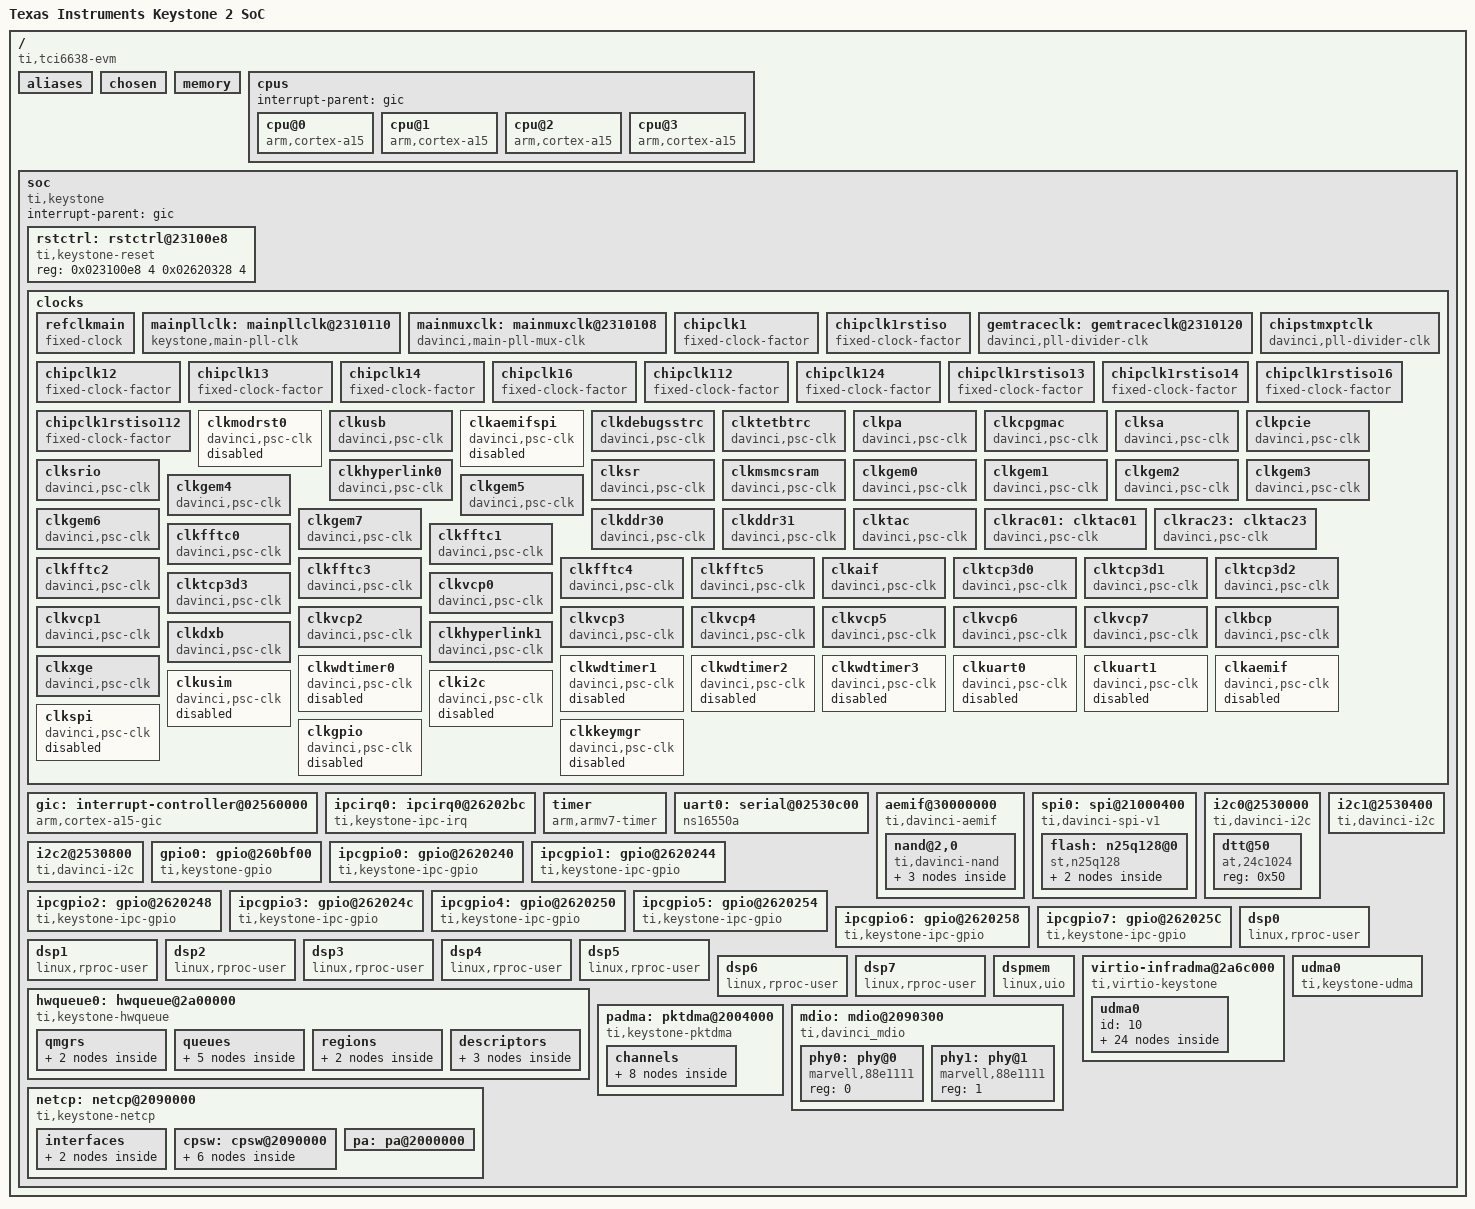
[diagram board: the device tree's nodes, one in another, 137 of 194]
/dts-v1/;
/include/ "skeleton.dtsi"

/ {
	model = "Texas Instruments Keystone 2 SoC";
	compatible = "ti,tci6638-evm";
	#address-cells = <2>;
	#size-cells = <2>;
	interrupt-parent = <&gic>;

	aliases {
		serial0	= &uart0;
		gpio0	= &gpio0;
	};

	chosen {
	};

	memory {
		reg = <0x00000000 0x80000000 0x00000000 0x20000000>;
	};

	cpus {
		interrupt-parent = <&gic>;

		cpu@0 {
			compatible = "arm,cortex-a15";
		};

		cpu@1 {
			compatible = "arm,cortex-a15";
		};

		cpu@2 {
			compatible = "arm,cortex-a15";
		};

		cpu@3 {
			compatible = "arm,cortex-a15";
		};
	};

	soc {
		#address-cells = <1>;
		#size-cells = <1>;
		compatible = "ti,keystone","simple-bus";
		interrupt-parent = <&gic>;
		ranges = <0x0 0x0 0x0 0xc0000000>;

		rstctrl:rstctrl@23100e8 {
			compatible = "ti,keystone-reset";
			reg = <0x023100e8 4	/* pll reset control reg */
				0x02620328 4>;	/* rstmux8 register */
		};

		clocks {
			#address-cells = <1>;
			#size-cells = <1>;
			ranges;

			refclkmain: refclkmain {
				#clock-cells = <0>;
				compatible = "fixed-clock";
				clock-frequency = <122880000>;
				clock-output-names = "refclk-main";
			};

			mainpllclk: mainpllclk@2310110 {
				#clock-cells = <0>;
				compatible = "keystone,main-pll-clk";
				clocks = <&refclkmain>;
				reg = <0x02310110 4	/* PLLCTRL PLLM */
					0x02620350 4>;	/* MAINPLL_CTL0 */
				pllm_lower_mask	= <0x3f>;
				pllm_upper_mask = <0x7f000>;
				pllm_upper_shift = <6>;
				plld_mask = <0x3f>;
				fixed_postdiv = <2>;
			};

			mainmuxclk: mainmuxclk@2310108 {
				#clock-cells = <0>;
				compatible = "davinci,main-pll-mux-clk";
				clocks = <&mainpllclk>, <&refclkmain>;
				reg = <0x02310108 4>;
				shift = <23>;
				width = <1>;
			};

			chipclk1: chipclk1 {
				#clock-cells = <0>;
				compatible = "fixed-clock-factor";
				clocks = <&mainmuxclk>;
				mult = <1>;
				div = <1>;
			};

			chipclk1rstiso: chipclk1rstiso {
				#clock-cells = <0>;
				compatible = "fixed-clock-factor";
				clocks = <&mainmuxclk>;
				mult = <1>;
				div = <1>;
			};

			gemtraceclk: gemtraceclk@2310120 {
				#clock-cells = <0>;
				compatible = "davinci,pll-divider-clk";
				clocks = <&mainmuxclk>;
				reg = <0x02310120 4>;
				shift = <0>;
				width = <8>;
			};

			chipstmxptclk: chipstmxptclk {
				#clock-cells = <0>;
				compatible = "davinci,pll-divider-clk";
				clocks = <&mainmuxclk>;
				reg = <0x02310164 4>;
				shift = <0>;
				width = <8>;
			};

			chipclk12: chipclk12 {
				#clock-cells = <0>;
				compatible = "fixed-clock-factor";
				clocks = <&chipclk1>;
				mult = <1>;
				div = <2>;
			};

			chipclk13: chipclk13 {
				#clock-cells = <0>;
				compatible = "fixed-clock-factor";
				clocks = <&chipclk1>;
				mult = <1>;
				div = <3>;
			};

			chipclk14: chipclk14 {
				#clock-cells = <0>;
				compatible = "fixed-clock-factor";
				clocks = <&chipclk1>;
				mult = <1>;
				div = <4>;
			};

			chipclk16: chipclk16 {
				#clock-cells = <0>;
				compatible = "fixed-clock-factor";
				clocks = <&chipclk1>;
				mult = <1>;
				div = <6>;
			};

			chipclk112: chipclk112 {
				#clock-cells = <0>;
				compatible = "fixed-clock-factor";
				clocks = <&chipclk1>;
				mult = <1>;
				div = <12>;
			};

			chipclk124: chipclk124 {
				#clock-cells = <0>;
				compatible = "fixed-clock-factor";
				clocks = <&chipclk1>;
				mult = <1>;
				div = <24>;
			};

			chipclk1rstiso13: chipclk1rstiso13 {
				#clock-cells = <0>;
				compatible = "fixed-clock-factor";
				clocks = <&chipclk1rstiso>;
				mult = <1>;
				div = <3>;
			};

			chipclk1rstiso14: chipclk1rstiso14 {
				#clock-cells = <0>;
				compatible = "fixed-clock-factor";
				clocks = <&chipclk1rstiso>;
				mult = <1>;
				div = <4>;
			};

			chipclk1rstiso16: chipclk1rstiso16 {
				#clock-cells = <0>;
				compatible = "fixed-clock-factor";
				clocks = <&chipclk1rstiso>;
				mult = <1>;
				div = <6>;
			};

			chipclk1rstiso112: chipclk1rstiso112 {
				#clock-cells = <0>;
				compatible = "fixed-clock-factor";
				clocks = <&chipclk1rstiso>;
				mult = <1>;
				div = <12>;
			};

			clkmodrst0: clkmodrst0 {
				#clock-cells = <0>;
				compatible = "davinci,psc-clk";
				clocks = <&chipclk16>;
				clock-output-names = "modrst0";
				status = "enabled";
				reg = <0x02350000 4096>;
			};


			clkusb: clkusb {
				#clock-cells = <0>;
				compatible = "davinci,psc-clk";
				clocks = <&chipclk16>;
				clock-output-names = "usb";
				reg = <0x02350000 4096>;
				lpsc = <2>;
			};

			clkaemifspi: clkaemifspi {
				#clock-cells = <0>;
				compatible = "davinci,psc-clk";
				clocks = <&chipclk16>;
				clock-output-names = "aemif-spi";
				reg = <0x02350000 4096>;
				status = "enabled";
				lpsc = <3>;
			};


			clkdebugsstrc: clkdebugsstrc {
				#clock-cells = <0>;
				compatible = "davinci,psc-clk";
				clocks = <&chipclk13>;
				clock-output-names = "debugss-trc";
				base-flags = "ignore-unused";
				reg = <0x02350000 4096>;
				lpsc = <5>;
				pd = <1>;
			};

			clktetbtrc: clktetbtrc {
				#clock-cells = <0>;
				compatible = "davinci,psc-clk";
				clocks = <&chipclk13>;
				clock-output-names = "tetb-trc";
				base-flags = "ignore-unused";
				reg = <0x02350000 4096>;
				lpsc = <6>;
				pd = <1>;
			};

			clkpa: clkpa {
				#clock-cells = <0>;
				compatible = "davinci,psc-clk";
				clocks = <&chipclk16>;
				clock-output-names = "pa";
				base-flags = "ignore-unused";
				reg = <0x02350000 4096>;
				lpsc = <7>;
				pd = <2>;
			};

			clkcpgmac: clkcpgmac {
				#clock-cells = <0>;
				compatible = "davinci,psc-clk";
				clocks = <&clkpa>;
				clock-output-names = "cpgmac";
				base-flags = "ignore-unused";
				reg = <0x02350000 4096>;
				lpsc = <8>;
				pd = <2>;
			};

			clksa: clksa {
				#clock-cells = <0>;
				compatible = "davinci,psc-clk";
				clocks = <&clkpa>;
				clock-output-names = "sa";
				base-flags = "ignore-unused";
				reg = <0x02350000 4096>;
				lpsc = <9>;
				pd = <2>;
			};

			clkpcie: clkpcie {
				#clock-cells = <0>;
				compatible = "davinci,psc-clk";
				clocks = <&chipclk12>;
				clock-output-names = "pcie";
				base-flags = "ignore-unused";
				reg = <0x02350000 4096>;
				lpsc = <10>;
				pd = <3>;
			};

			clksrio: clksrio {
				#clock-cells = <0>;
				compatible = "davinci,psc-clk";
				clocks = <&chipclk1rstiso13>;
				clock-output-names = "srio";
				base-flags = "ignore-unused";
				reg = <0x02350000 4096>;
				lpsc = <11>;
				pd = <4>;
			};

			clkhyperlink0: clkhyperlink0 {
				#clock-cells = <0>;
				compatible = "davinci,psc-clk";
				clocks = <&chipclk12>;
				clock-output-names = "hyperlink-0";
				base-flags = "ignore-unused";
				reg = <0x02350000 4096>;
				lpsc = <12>;
				pd = <5>;
			};

			clksr: clksr {
				#clock-cells = <0>;
				compatible = "davinci,psc-clk";
				clocks = <&chipclk1rstiso112>;
				clock-output-names = "sr";
				base-flags = "ignore-unused";
				reg = <0x02350000 4096>;
				lpsc = <13>;
				pd = <6>;
			};

			clkmsmcsram: clkmsmcsram {
				#clock-cells = <0>;
				compatible = "davinci,psc-clk";
				clocks = <&chipclk1>;
				clock-output-names = "msmcsram";
				base-flags = "ignore-unused";
				reg = <0x02350000 4096>;
				lpsc = <14>;
				pd = <7>;
			};

			clkgem0: clkgem0 {
				#clock-cells = <0>;
				compatible = "davinci,psc-clk";
				clocks = <&chipclk1>;
				clock-output-names = "gem0";
				base-flags = "ignore-unused";
				reg = <0x02350000 4096>;
				lpsc = <15>;
				pd = <8>;
			};

			clkgem1: clkgem1 {
				#clock-cells = <0>;
				compatible = "davinci,psc-clk";
				clocks = <&chipclk1>;
				clock-output-names = "gem1";
				base-flags = "ignore-unused";
				reg = <0x02350000 4096>;
				lpsc = <16>;
				pd = <9>;
			};

			clkgem2: clkgem2 {
				#clock-cells = <0>;
				compatible = "davinci,psc-clk";
				clocks = <&chipclk1>;
				clock-output-names = "gem2";
				base-flags = "ignore-unused";
				reg = <0x02350000 4096>;
				lpsc = <17>;
				pd = <10>;
			};

			clkgem3: clkgem3 {
				#clock-cells = <0>;
				compatible = "davinci,psc-clk";
				clocks = <&chipclk1>;
				clock-output-names = "gem3";
				base-flags = "ignore-unused";
				reg = <0x02350000 4096>;
				lpsc = <18>;
				pd = <11>;
			};

			clkgem4: clkgem4 {
				#clock-cells = <0>;
				compatible = "davinci,psc-clk";
				clocks = <&chipclk1>;
				clock-output-names = "gem4";
				base-flags = "ignore-unused";
				reg = <0x02350000 4096>;
				lpsc = <19>;
				pd = <12>;
			};

			clkgem5: clkgem5 {
				#clock-cells = <0>;
				compatible = "davinci,psc-clk";
				clocks = <&chipclk1>;
				clock-output-names = "gem5";
				base-flags = "ignore-unused";
				reg = <0x02350000 4096>;
				lpsc = <20>;
				pd = <13>;
			};

			clkgem6: clkgem6 {
				#clock-cells = <0>;
				compatible = "davinci,psc-clk";
				clocks = <&chipclk1>;
				clock-output-names = "gem6";
				base-flags = "ignore-unused";
				reg = <0x02350000 4096>;
				lpsc = <21>;
				pd = <14>;
			};

			clkgem7: clkgem7 {
				#clock-cells = <0>;
				compatible = "davinci,psc-clk";
				clocks = <&chipclk1>;
				clock-output-names = "gem7";
				base-flags = "ignore-unused";
				reg = <0x02350000 4096>;
				lpsc = <22>;
				pd = <15>;
			};

			clkddr30: clkddr30 {
				#clock-cells = <0>;
				compatible = "davinci,psc-clk";
				clocks = <&chipclk12>;
				clock-output-names = "ddr3-0";
				base-flags = "ignore-unused";
				reg = <0x02350000 4096>;
				lpsc = <23>;
				pd = <16>;
			};

			clkddr31: clkddr31 {
				#clock-cells = <0>;
				compatible = "davinci,psc-clk";
				clocks = <&chipclk13>;
				clock-output-names = "ddr3-1";
				base-flags = "ignore-unused";
				reg = <0x02350000 4096>;
				lpsc = <24>;
				pd = <16>;
			};

			clktac: clktac {
				#clock-cells = <0>;
				compatible = "davinci,psc-clk";
				clocks = <&chipclk13>;
				clock-output-names = "tac";
				base-flags = "ignore-unused";
				reg = <0x02350000 4096>;
				lpsc = <25>;
				pd = <17>;
			};

			clkrac01: clktac01 {
				#clock-cells = <0>;
				compatible = "davinci,psc-clk";
				clocks = <&chipclk13>;
				clock-output-names = "rac-01";
				base-flags = "ignore-unused";
				reg = <0x02350000 4096>;
				lpsc = <26>;
				pd = <17>;
			};

			clkrac23: clktac23 {
				#clock-cells = <0>;
				compatible = "davinci,psc-clk";
				clocks = <&chipclk13>;
				clock-output-names = "rac-23";
				base-flags = "ignore-unused";
				reg = <0x02350000 4096>;
				lpsc = <27>;
				pd = <18>;
			};

			clkfftc0: clkfftc0 {
				#clock-cells = <0>;
				compatible = "davinci,psc-clk";
				clocks = <&chipclk13>;
				clock-output-names = "fftc-0";
				base-flags = "ignore-unused";
				reg = <0x02350000 4096>;
				lpsc = <28>;
				pd = <19>;
			};

			clkfftc1: clkfftc1 {
				#clock-cells = <0>;
				compatible = "davinci,psc-clk";
				clocks = <&chipclk13>;
				clock-output-names = "fftc-1";
				base-flags = "ignore-unused";
				reg = <0x02350000 4096>;
				lpsc = <29>;
				pd = <19>;
			};

			clkfftc2: clkfftc2 {
				#clock-cells = <0>;
				compatible = "davinci,psc-clk";
				clocks = <&chipclk13>;
				clock-output-names = "fftc-2";
				base-flags = "ignore-unused";
				reg = <0x02350000 4096>;
				lpsc = <30>;
				pd = <20>;
			};

			clkfftc3: clkfftc3 {
				#clock-cells = <0>;
				compatible = "davinci,psc-clk";
				clocks = <&chipclk13>;
				clock-output-names = "fftc-3";
				base-flags = "ignore-unused";
				reg = <0x02350000 4096>;
				lpsc = <31>;
				pd = <20>;
			};

			clkfftc4: clkfftc4 {
				#clock-cells = <0>;
				compatible = "davinci,psc-clk";
				clocks = <&chipclk13>;
				clock-output-names = "fftc-4";
				base-flags = "ignore-unused";
				reg = <0x02350000 4096>;
				lpsc = <32>;
				pd = <20>;
			};

			clkfftc5: clkfftc5 {
				#clock-cells = <0>;
				compatible = "davinci,psc-clk";
				clocks = <&chipclk13>;
				clock-output-names = "fftc-5";
				base-flags = "ignore-unused";
				reg = <0x02350000 4096>;
				lpsc = <33>;
				pd = <20>;
			};

			clkaif: clkaif {
				#clock-cells = <0>;
				compatible = "davinci,psc-clk";
				clocks = <&chipclk13>;
				clock-output-names = "aif";
				base-flags = "ignore-unused";
				reg = <0x02350000 4096>;
				lpsc = <34>;
				pd = <21>;
			};

			clktcp3d0: clktcp3d0 {
				#clock-cells = <0>;
				compatible = "davinci,psc-clk";
				clocks = <&chipclk13>;
				clock-output-names = "tcp3d-0";
				base-flags = "ignore-unused";
				reg = <0x02350000 4096>;
				lpsc = <35>;
				pd = <22>;
			};

			clktcp3d1: clktcp3d1 {
				#clock-cells = <0>;
				compatible = "davinci,psc-clk";
				clocks = <&chipclk13>;
				clock-output-names = "tcp3d-1";
				base-flags = "ignore-unused";
				reg = <0x02350000 4096>;
				lpsc = <36>;
				pd = <22>;
			};

			clktcp3d2: clktcp3d2 {
				#clock-cells = <0>;
				compatible = "davinci,psc-clk";
				clocks = <&chipclk13>;
				clock-output-names = "tcp3d-2";
				base-flags = "ignore-unused";
				reg = <0x02350000 4096>;
				lpsc = <37>;
				pd = <23>;
			};

			clktcp3d3: clktcp3d3 {
				#clock-cells = <0>;
				compatible = "davinci,psc-clk";
				clocks = <&chipclk13>;
				clock-output-names = "tcp3d-3";
				base-flags = "ignore-unused";
				reg = <0x02350000 4096>;
				lpsc = <38>;
				pd = <23>;
			};

			clkvcp0: clkvcp0 {
				#clock-cells = <0>;
				compatible = "davinci,psc-clk";
				clocks = <&chipclk13>;
				clock-output-names = "vcp-0";
				base-flags = "ignore-unused";
				reg = <0x02350000 4096>;
				lpsc = <39>;
				pd = <24>;
			};

			clkvcp1: clkvcp1 {
				#clock-cells = <0>;
				compatible = "davinci,psc-clk";
				clocks = <&chipclk13>;
				clock-output-names = "vcp-1";
				base-flags = "ignore-unused";
				reg = <0x02350000 4096>;
				lpsc = <40>;
				pd = <24>;
			};

			clkvcp2: clkvcp2 {
				#clock-cells = <0>;
				compatible = "davinci,psc-clk";
				clocks = <&chipclk13>;
				clock-output-names = "vcp-2";
				base-flags = "ignore-unused";
				reg = <0x02350000 4096>;
				lpsc = <41>;
				pd = <24>;
			};

			clkvcp3: clkvcp3 {
				#clock-cells = <0>;
				compatible = "davinci,psc-clk";
				clocks = <&chipclk13>;
				clock-output-names = "vcp-3";
				base-flags = "ignore-unused";
				reg = <0x02350000 4096>;
				lpsc = <42>;
				pd = <24>;
			};

			clkvcp4: clkvcp4 {
				#clock-cells = <0>;
				compatible = "davinci,psc-clk";
				clocks = <&chipclk13>;
				clock-output-names = "vcp-4";
				base-flags = "ignore-unused";
				reg = <0x02350000 4096>;
				lpsc = <43>;
				pd = <25>;
			};

			clkvcp5: clkvcp5 {
				#clock-cells = <0>;
				compatible = "davinci,psc-clk";
				clocks = <&chipclk13>;
				clock-output-names = "vcp-5";
				base-flags = "ignore-unused";
				reg = <0x02350000 4096>;
				lpsc = <44>;
				pd = <25>;
			};

			clkvcp6: clkvcp6 {
				#clock-cells = <0>;
				compatible = "davinci,psc-clk";
				clocks = <&chipclk13>;
				clock-output-names = "vcp-6";
				base-flags = "ignore-unused";
				reg = <0x02350000 4096>;
				lpsc = <45>;
				pd = <25>;
			};

			clkvcp7: clkvcp7 {
				#clock-cells = <0>;
				compatible = "davinci,psc-clk";
				clocks = <&chipclk13>;
				clock-output-names = "vcp-7";
				base-flags = "ignore-unused";
				reg = <0x02350000 4096>;
				lpsc = <46>;
				pd = <25>;
			};

			clkbcp: clkbcp {
				#clock-cells = <0>;
				compatible = "davinci,psc-clk";
				clocks = <&chipclk13>;
				clock-output-names = "bcp";
				base-flags = "ignore-unused";
				reg = <0x02350000 4096>;
				lpsc = <47>;
				pd = <26>;
			};

			clkdxb: clkdxb {
				#clock-cells = <0>;
				compatible = "davinci,psc-clk";
				clocks = <&chipclk13>;
				clock-output-names = "dxb";
				base-flags = "ignore-unused";
				reg = <0x02350000 4096>;
				lpsc = <48>;
				pd = <27>;
			};

			clkhyperlink1: clkhyperlink1 {
				#clock-cells = <0>;
				compatible = "davinci,psc-clk";
				clocks = <&chipclk12>;
				clock-output-names = "hyperlink-1";
				base-flags = "ignore-unused";
				reg = <0x02350000 4096>;
				lpsc = <49>;
				pd = <28>;
			};

			clkxge: clkxge {
				#clock-cells = <0>;
				compatible = "davinci,psc-clk";
				clocks = <&chipclk13>;
				clock-output-names = "xge";
				base-flags = "ignore-unused";
				reg = <0x02350000 4096>;
				lpsc = <50>;
				pd = <29>;
			};

			clkwdtimer0: clkwdtimer0 {
				#clock-cells = <0>;
				compatible = "davinci,psc-clk";
				clocks = <&clkmodrst0>;
				clock-output-names = "timer0";
				status = "enabled";
				reg = <0x02350000 4096>;
			};

			clkwdtimer1: clkwdtimer1 {
				#clock-cells = <0>;
				compatible = "davinci,psc-clk";
				clocks = <&clkmodrst0>;
				clock-output-names = "timer1";
				status = "enabled";
				reg = <0x02350000 4096>;
			};

			clkwdtimer2: clkwdtimer2 {
				#clock-cells = <0>;
				compatible = "davinci,psc-clk";
				clocks = <&clkmodrst0>;
				clock-output-names = "timer2";
				status = "enabled";
				reg = <0x02350000 4096>;
			};

			clkwdtimer3: clkwdtimer3 {
				#clock-cells = <0>;
				compatible = "davinci,psc-clk";
				clocks = <&clkmodrst0>;
				clock-output-names = "timer3";
				status = "enabled";
				reg = <0x02350000 4096>;
			};

			clkuart0: clkuart0 {
				#clock-cells = <0>;
				compatible = "davinci,psc-clk";
				clocks = <&clkmodrst0>;
				clock-output-names = "uart0";
				status = "enabled";
				reg = <0x02350000 4096>;
			};

			clkuart1: clkuart1 {
				#clock-cells = <0>;
				compatible = "davinci,psc-clk";
				clocks = <&clkmodrst0>;
				clock-output-names = "uart1";
				status = "enabled";
				reg = <0x02350000 4096>;
			};

			clkaemif: clkaemif {
				#clock-cells = <0>;
				compatible = "davinci,psc-clk";
				clocks = <&clkaemifspi>;
				clock-output-names = "aemif";
				status = "enabled";
				reg = <0x02350000 4096>;
			};

			clkusim: clkusim {
				#clock-cells = <0>;
				compatible = "davinci,psc-clk";
				clocks = <&clkmodrst0>;
				clock-output-names = "usim";
				status = "enabled";
				reg = <0x02350000 4096>;
			};

			clki2c: clki2c {
				#clock-cells = <0>;
				compatible = "davinci,psc-clk";
				clocks = <&clkmodrst0>;
				clock-output-names = "i2c";
				status = "enabled";
				reg = <0x02350000 4096>;
			};

			clkspi: clkspi {
				#clock-cells = <0>;
				compatible = "davinci,psc-clk";
				clocks = <&clkaemifspi>;
				clock-output-names = "spi";
				status = "enabled";
				reg = <0x02350000 4096>;
			};

			clkgpio: clkgpio {
				#clock-cells = <0>;
				compatible = "davinci,psc-clk";
				clocks = <&clkmodrst0>;
				clock-output-names = "gpio";
				status = "enabled";
				reg = <0x02350000 4096>;
			};

			clkkeymgr: clkkeymgr {
				#clock-cells = <0>;
				compatible = "davinci,psc-clk";
				clocks = <&clkmodrst0>;
				clock-output-names = "keymgr";
				status = "enabled";
				reg = <0x02350000 4096>;
			};

		};

		gic:	interrupt-controller@02560000 {
			compatible = "arm,cortex-a15-gic";
			#interrupt-cells = <3>;
			#size-cells = <0>;
			#address-cells = <1>;
			interrupt-controller;
			reg = <0x02561000 0x1000>,
			      <0x02562000 0x2000>;
		};

		ipcirq0: ipcirq0@26202bc {	/* ipc irq chip */
			compatible = "ti,keystone-ipc-irq";
			reg  = <0x026202a0 4	/* host ack register */
			        0x02620260 4>;	/* ipc host interrupt generation register */
			interrupts = <0 4 0x101>;/* it should match the value in irqs.h */
						 /* following is the source id to irq mapping
						   SRCS0 <-> ipc hw irq 0 ... SRCS27 <-> ipc hw irq 27
						   note that SRCS0 is bit 4 in ipc register */
			interrupt-controller;
			#interrupt-cells = <2>;
		};

		timer {
			compatible = "arm,armv7-timer";
			interrupts = <1 13 0xf08 1 14 0xf08>;
			clock-frequency = <133666666>; /* Freq in Hz - optional */
		};

		uart0:	serial@02530c00 {
			compatible	= "ns16550a";
			current-speed	= <115200>;
			reg-shift	= <2>;
			reg-io-width	= <4>;
			reg		= <0x02530c00 0x100>;
			clocks		= <&clkuart0>;
			interrupts	= <0 277 0xf01>;
		};

		aemif@30000000 {
			compatible = "ti,davinci-aemif";
			#address-cells = <2>;
			#size-cells = <1>;
			reg = <0x21000A00 0x100>;
			ranges = <2 0 0x30000000 0x08000000
				3 0 0x34000000 0x04000000
				4 0 0x38000000 0x04000000
				5 0 0x3C000000 0x04000000
				6 0 0x21000A00 0x100>;
			clocks = <&clkaemif>;
			clock-names = "aemif";

			nand@2,0 {
				compatible = "ti,davinci-nand";
				reg = <2 0x0 0x8000000
					6 0x0 0x100>;
				#address-cells = <1>;
				#size-cells = <1>;
				ti,davinci-chipselect = <0>;
				ti,davinci-mask-ale = <0x2000>;
				ti,davinci-mask-cle = <0x4000>;
				ti,davinci-mask-chipsel = <0>;
				ti,davinci-ecc-mode = "hw";
				ti,davinci-ecc-bits = <4>;
				ti,davinci-nand-use-bbt;
				ti,davinci-no-subpage-write;
				clocks = <&clkaemif>;
				clock-names = "aemif";

				partition@0 {
					label = "u-boot";
					reg = <0x0 0x100000>;
					read-only;
				};

				partition@100000 {
					label = "params";
					reg = <0x100000 0x80000>;
					read-only;
				};

				partition@180000 {
					label = "ubifs";
					reg = <0x180000 0x7e80000>;
				};
			};
		};

		spi0:spi@21000400 {
			#address-cells			= <1>;
			#size-cells			= <0>;
			compatible			= "ti,davinci-spi-v1";
			reg				= <0x21000400 0x200>;
			ti,davinci-spi-num-cs		= <4>;
			ti,davinci-spi-intr-line	= <0>;
			interrupts			= <0 292 0xf01>;
			clocks				= <&clkspi>;

			flash: n25q128@0 {
				#address-cells = <1>;
				#size-cells = <1>;
				compatible = "st,n25q128","st,m25p";
				spi-max-frequency = <30000000>;
				reg = <0>;

				partition@0 {
					label = "u-boot-spl";
					reg = <0x0 0x80000>;
					read-only;
				};

				partition@1 {
					label = "test";
					reg = <0x80000 0xf80000>;
				};
			};
		};

		i2c0@2530000 {
			compatible = "ti,davinci-i2c";
			reg = <0x02530000 0x400>;
			clock-frequency = <100000>;
			clocks		= <&clki2c>;
			interrupts	= <0 283 0xf01>;
			#address-cells = <1>;
			#size-cells = <0>;

			dtt@50 {
				compatible = "at,24c1024";
				reg = <0x50>;
			};
		};

		i2c1@2530400 {
			compatible = "ti,davinci-i2c";
			reg = <0x02530400 0x400>;
			clock-frequency = <100000>;
			clocks		= <&clki2c>;
			interrupts	= <0 286 0xf01>;
			#address-cells = <1>;
			#size-cells = <0>;

		};

		i2c2@2530800 {
			compatible = "ti,davinci-i2c";
			reg = <0x02530800 0x400>;
			clock-frequency = <100000>;
			clocks		= <&clki2c>;
			interrupts	= <0 289 0xf01>;
			#address-cells = <1>;
			#size-cells = <0>;

		};

		gpio0: gpio@260bf00 {
			compatible = "ti,keystone-gpio";
			reg = <0x0260bf00 0x10
				0x0260bf10 0x28>;
			gpio-controller;
			#gpio-cells = <2>;
			/* HW Interrupts mapped to GPIO pins */
			interrupts = <0 120 0xf01 0 121 0xf01 0 122 0xf01 0 123 0xf01 0 124 0xf01
					0 125 0xf01 0 126 0xf01 0 127 0xf01 0 128 0xf01 0 129 0xf01
					0 130 0xf01 0 131 0xf01 0 132 0xf01 0 133 0xf01 0 134 0xf01
					0 135 0xf01 0 136 0xf01 0 137 0xf01 0 138 0xf01 0 139 0xf01
					0 140 0xf01 0 141 0xf01 0 142 0xf01 0 143 0xf01 0 144 0xf01
					0 145 0xf01 0 146 0xf01 0 147 0xf01 0 148 0xf01 0 149 0xf01
					0 150 0xf01 0 151 0xf01>;
			interrupt-controller;
			#interrupt-cells = <2>;
			clocks = <&clkgpio>;
			clock-names = "gpio";
		};

		ipcgpio0: gpio@2620240 {
			compatible = "ti,keystone-ipc-gpio";
			reg = <0x02620240 4>;
			gpio-controller;
			#gpio-cells = <2>;
		};

		ipcgpio1: gpio@2620244 {
			compatible = "ti,keystone-ipc-gpio";
			reg = <0x02620244 4>;
			gpio-controller;
			#gpio-cells = <2>;
		};

		ipcgpio2: gpio@2620248 {
			compatible = "ti,keystone-ipc-gpio";
			reg = <0x02620248 4>;
			gpio-controller;
			#gpio-cells = <2>;
		};

		ipcgpio3: gpio@262024c {
			compatible = "ti,keystone-ipc-gpio";
			reg = <0x0262024c 4>;
			gpio-controller;
			#gpio-cells = <2>;
		};

		ipcgpio4: gpio@2620250 {
			compatible = "ti,keystone-ipc-gpio";
			reg = <0x02620250 4>;
			gpio-controller;
			#gpio-cells = <2>;
		};

		ipcgpio5: gpio@2620254 {
			compatible = "ti,keystone-ipc-gpio";
			reg = <0x02620254 4>;
			gpio-controller;
			#gpio-cells = <2>;
		};

		ipcgpio6: gpio@2620258 {
			compatible = "ti,keystone-ipc-gpio";
			reg = <0x02620258 4>;
			gpio-controller;
			#gpio-cells = <2>;
		};

		ipcgpio7: gpio@262025C {
			compatible = "ti,keystone-ipc-gpio";
			reg = <0x0262025C 4>;
			gpio-controller;
			#gpio-cells = <2>;
		};

		dsp0: dsp0 {
			compatible = "linux,rproc-user";
			reg = <0x02620040 4
			       0x0235083c 4
			       0x02350a3c 4
			       0x02620240 4
			       0x10800000 0x00100000>;
			reg-names = "boot-address", "psc-mdstat", "psc-mdctl", "ipcgr", "l2ram";
			interrupt-parent = <&ipcirq0>;
			interrupts = <8 0 0 0>;
			kick-gpio = <&ipcgpio0 27 0>;
			clocks = <&clkgem0>;
		};

		dsp1: dsp1 {
			compatible = "linux,rproc-user";
			reg = <0x02620044 4
			       0x02350840 4
			       0x02350a40 4
			       0x02620244 4
			       0x11800000 0x00100000>;
			reg-names = "boot-address", "psc-mdstat", "psc-mdctl", "ipcgr", "l2ram";
			interrupt-parent = <&ipcirq0>;
			interrupts = <9 0 1 0>;
			kick-gpio = <&ipcgpio1 27 0>;
			clocks = <&clkgem1>;
		};

		dsp2: dsp2 {
			compatible = "linux,rproc-user";
			reg = <0x02620048 4
			       0x02350844 4
			       0x02350a44 4
			       0x02620248 4
			       0x12800000 0x00100000>;
			reg-names = "boot-address", "psc-mdstat", "psc-mdctl", "ipcgr", "l2ram";
			interrupt-parent = <&ipcirq0>;
			interrupts = <10 0 2 0>;
			kick-gpio = <&ipcgpio2 27 0>;
			clocks = <&clkgem2>;
		};

		dsp3: dsp3 {
			compatible = "linux,rproc-user";
			reg = <0x0262004c 4
			       0x02350848 4
			       0x02350a48 4
			       0x0262024c 4
			       0x13800000 0x00100000>;
			reg-names = "boot-address", "psc-mdstat", "psc-mdctl", "ipcgr", "l2ram";
			interrupt-parent = <&ipcirq0>;
			interrupts = <11 0 3 0>;
			kick-gpio = <&ipcgpio3 27 0>;
			clocks = <&clkgem3>;
		};

		dsp4: dsp4 {
			compatible = "linux,rproc-user";
			reg = <0x02620050 4
			       0x0235084C 4
			       0x02350a4C 4
			       0x02620250 4
			       0x14800000 0x00100000>;
			reg-names = "boot-address", "psc-mdstat", "psc-mdctl", "ipcgr", "l2ram";
			interrupt-parent = <&ipcirq0>;
			interrupts = <12 0 4 0>;
			kick-gpio = <&ipcgpio4 27 0>;
			clocks = <&clkgem4>;
		};

		dsp5: dsp5 {
			compatible = "linux,rproc-user";
			reg = <0x02620054 4
			       0x02350850 4
			       0x02350a50 4
			       0x02620254 4
			       0x15800000 0x00100000>;
			reg-names = "boot-address", "psc-mdstat", "psc-mdctl", "ipcgr", "l2ram";
			interrupt-parent = <&ipcirq0>;
			interrupts = <13 0 5 0>;
			kick-gpio = <&ipcgpio5 27 0>;
			clocks = <&clkgem5>;
		};

		dsp6: dsp6 {
			compatible = "linux,rproc-user";
			reg = <0x02620058 4
			       0x02350854 4
			       0x02350a54 4
			       0x02620258 4
			       0x16800000 0x00100000>;
			reg-names = "boot-address", "psc-mdstat", "psc-mdctl", "ipcgr", "l2ram";
			interrupt-parent = <&ipcirq0>;
			interrupts = <14 0 6 0>;
			kick-gpio = <&ipcgpio6 27 0>;
			clocks = <&clkgem6>;
		};

		dsp7: dsp7 {
			compatible = "linux,rproc-user";
			reg = <0x0262005C 4
			       0x02350858 4
			       0x02350a58 4
			       0x0262025C 4
			       0x17800000 0x00100000>;
			reg-names = "boot-address", "psc-mdstat", "psc-mdctl", "ipcgr", "l2ram";
			interrupt-parent = <&ipcirq0>;
			interrupts = <15 0 7 0>;
			kick-gpio = <&ipcgpio7 27 0>;
			clocks = <&clkgem7>;
		};

		dspmem: dspmem {
			compatible = "linux,uio";
			reg  = <0x0c000000 0x00200000	/* msmc ram */
				0xa0000000 0x20000000>;	/* corepac's ddr3 */
			reg-names = "msmcram", "ddr3";
		};

		hwqueue0: hwqueue@2a00000 {
			compatible = "ti,keystone-hwqueue";
			#address-cells = <1>;
			#size-cells = <1>;
			ranges;
			range		= <0 0x4000>;
			linkram0	= <0x100000 0x8000>;
			linkram1	= <0x0 0x10000>;

			qmgrs {
				#address-cells = <1>;
				#size-cells = <1>;
				ranges;
				qmgr0 {
					managed-queues = <0 0x2000>;	/* managed queues */
					reg = <0x2a40000 0x20000	/* 0 - peek	*/
					       0x2a06000 0x400		/* 1 - status	*/
					       0x2a02000 0x1000		/* 2 - config	*/
					       0x2a03000 0x1000		/* 3 - region	*/
					       0x2a80000 0x20000	/* 4 - push	*/
					       0x2a80000 0x20000>;	/* 5 - pop	*/
				};

				qmgr1 {
					managed-queues = <0x2000 0x2000>;	/* managed queues */
					reg = <0x2a60000 0x20000	/* 0 - peek	*/
					       0x2a06400 0x400		/* 1 - status	*/
					       0x2a04000 0x1000		/* 2 - config	*/
					       0x2a05000 0x1000		/* 3 - region	*/
					       0x2aa0000 0x20000	/* 4 - push	*/
					       0x2aa0000 0x20000>;	/* 5 - pop	*/
				};
			};
			queues {
				qpend-arm-low {
					values = <652 20>;
					interrupts = <0 40 0xf04 0 41 0xf04 0 42 0xf04 0 43 0xf04
						      0 44 0xf04 0 45 0xf04 0 46 0xf04 0 47 0xf04>;
					reserved;
				};
				qpend-arm-hi {
					values = <8704 32>;
					interrupts = <0 48 0xf04 0 49 0xf04 0 50 0xf04 0 51 0xf04
						      0 52 0xf04 0 53 0xf04 0 54 0xf04 0 55 0xf04
						      0 56 0xf04 0 57 0xf04 0 58 0xf04 0 59 0xf04
						      0 60 0xf04 0 61 0xf04 0 62 0xf04 0 63 0xf04
						      0 64 0xf04 0 65 0xf04 0 66 0xf04 0 59 0xf04
						      0 68 0xf04 0 69 0xf04 0 70 0xf04 0 71 0xf04
						      0 72 0xf04 0 73 0xf04 0 74 0xf04 0 75 0xf04
						      0 76 0xf04 0 77 0xf04 0 78 0xf04 0 79 0xf04>;
					reserved;
				};
				general {
					values = <4000 64>;
				};
				pa {
					values = <640 9>;
					reserved;
				};
				infradma {
					values = <800 12>;
					reserved;
				};
			};
			regions {
				#address-cells = <1>;
				#size-cells = <1>;
				ranges;
				region-12 {
					id = <12>;
					values	= <2048 128>;	/* num_desc desc_size */
					link-index = <0x4000>;
				};
				region-13 {
					id = <13>;
					values	= <2048 256>;	/* num_desc desc_size */
					link-index = <0x4800>;
				};
			};
			descriptors {
				pool-net {
					values = <2048 128>;	/* num_desc desc_size */
					region-id = <12>;
				};
				pool-rio {
					values = <128 256>;
					region-id = <13>;
				};
				pool-udma {
					values = <1636 256>;	/* num_desc desc_size */
					region-id = <13>;
				};
			};
		}; /* hwqueue0 */

		virtio-infradma@2a6c000 {
			compatible = "ti,virtio-keystone";
			reg = <0x2a08000 0x100		/* 0 - global  */
			       0x2a08400 0x400		/* 1 - txchan  */
			       0x2a08800 0x400		/* 2 - rxchan  */
			       0x2a08c00 0x080		/* 3 - txsched */
			       0x2a09000 0x400>;	/* 4 - rxflow  */
			loop-back;
			/* big-endian; */
			enable-all;
			debug;
			/* rx-priority = <0>; */
			/* tx-priority = <0>; */
			queue-managers = <0x23a80000 0x23a90000
					  0x23aa0000 0x23ab0000>;

			udma0 {
				id = <10>;
				udmatx0 {
					transmit;
					label		= "udmatx0";
					pool		= "pool-udma";
					submit-queue	= <800>;
					/* complete-queue  = <0> */
					/* debug; */
					channel		= <0>;
					priority	= <1>;
					flowtag		= <0>;
				};
				udmatx1 {
					transmit;
					label		= "udmatx1";
					pool		= "pool-udma";
					submit-queue	= <801>;
					/* complete-queue  = <1> */
					/* debug; */
					channel		= <1>;
					priority	= <1>;
					flowtag		= <1>;
				};
				udmatx2 {
					transmit;
					label		= "udmatx2";
					pool		= "pool-udma";
					submit-queue	= <802>;
					/* complete-queue  = <2> */
					/* debug; */
					channel		= <2>;
					priority	= <1>;
					flowtag		= <2>;
				};
				udmatx3 {
					transmit;
					label		= "udmatx3";
					pool		= "pool-udma";
					submit-queue	= <803>;
					/* complete-queue  = <3> */
					/* debug; */
					channel		= <3>;
					priority	= <1>;
					flowtag		= <3>;
				};
				udmatx4 {
					transmit;
					label		= "udmatx4";
					pool		= "pool-udma";
					submit-queue	= <804>;
					/* complete-queue  = <4> */
					/* debug; */
					channel		= <4>;
					priority	= <1>;
					flowtag		= <4>;
				};
				udmatx5 {
					transmit;
					label		= "udmatx5";
					pool		= "pool-udma";
					submit-queue	= <805>;
					/* complete-queue  = <5> */
					/* debug; */
					channel		= <5>;
					priority	= <1>;
					flowtag		= <5>;
				};
				udmatx6 {
					transmit;
					label		= "udmatx6";
					pool		= "pool-udma";
					submit-queue	= <806>;
					/* complete-queue  = <6> */
					/* debug; */
					channel		= <6>;
					priority	= <1>;
					flowtag		= <6>;
				};
				udmatx7 {
					transmit;
					label		= "udmatx7";
					pool		= "pool-udma";
					submit-queue	= <807>;
					/* complete-queue  = <7> */
					/* debug; */
					channel		= <7>;
					priority	= <1>;
					flowtag		= <7>;
				};
				udmatx8 {
					transmit;
					label		= "udmatx8";
					pool		= "pool-udma";
					submit-queue	= <808>;
					/* complete-queue  = <8> */
					/* debug; */
					channel		= <8>;
					priority	= <1>;
					flowtag		= <8>;
				};
				udmatx9 {
					transmit;
					label		= "udmatx9";
					pool		= "pool-udma";
					submit-queue	= <809>;
					/* complete-queue  = <9> */
					/* debug; */
					channel		= <9>;
					priority	= <1>;
					flowtag		= <9>;
				};
				udmatx10 {
					transmit;
					label		= "udmatx10";
					pool		= "pool-udma";
					submit-queue	= <810>;
					/* complete-queue  = <10> */
					/* debug; */
					channel		= <10>;
					priority	= <1>;
					flowtag		= <10>;
				};
				udmatx11 {
					transmit;
					label		= "udmatx11";
					pool		= "pool-udma";
					submit-queue	= <811>;
					/* complete-queue  = <11> */
					/* debug; */
					channel		= <11>;
					priority	= <1>;
					flowtag		= <11>;
				};
				udmarx0 {
					receive;
					label		= "udmarx0";
					pool		= "pool-udma";
					/* submit-queue = <xx>; */
					/* complete-queue  = <16> */
					/* debug; */
					channel		= <0>;
					flow		= <0>;
				};
				udmarx1 {
					receive;
					label		= "udmarx1";
					pool		= "pool-udma";
					/* submit-queue = <xx>; */
					/* complete-queue  = <17> */
					/* debug; */
					channel		= <1>;
					flow		= <1>;
				};
				udmarx2 {
					receive;
					label		= "udmarx2";
					pool		= "pool-udma";
					/* submit-queue = <xx>; */
					/* complete-queue  = <18> */
					/* debug; */
					channel		= <2>;
					flow		= <2>;
				};
				udmarx3 {
					receive;
					label		= "udmarx3";
					pool		= "pool-udma";
					/* submit-queue = <xx>; */
					/* complete-queue  = <19> */
					/* debug; */
					channel		= <3>;
					flow		= <3>;
				};
				udmarx4 {
					receive;
					label		= "udmarx4";
					pool		= "pool-udma";
					/* submit-queue = <xx>; */
					/* complete-queue  = <20> */
					/* debug; */
					channel		= <4>;
					flow		= <4>;
				};
				udmarx5 {
					receive;
					label		= "udmarx5";
					pool		= "pool-udma";
					/* submit-queue = <xx>; */
					/* complete-queue  = <21> */
					/* debug; */
					channel		= <5>;
					flow		= <5>;
				};
				udmarx6 {
					receive;
					label		= "udmarx6";
					pool		= "pool-udma";
					/* submit-queue = <xx>; */
					/* complete-queue  = <22> */
					/* debug; */
					channel		= <6>;
					flow		= <6>;
				};
				udmarx7 {
					receive;
					label		= "udmarx7";
					pool		= "pool-udma";
					/* submit-queue = <xx>; */
					/* complete-queue  = <23> */
					/* debug; */
					channel		= <7>;
					flow		= <7>;
				};
				udmarx8 {
					receive;
					label		= "udmarx8";
					pool		= "pool-udma";
					/* submit-queue = <xx>; */
					/* complete-queue  = <24> */
					/* debug; */
					channel		= <8>;
					flow		= <8>;
				};
				udmarx9 {
					receive;
					label		= "udmarx9";
					pool		= "pool-udma";
					/* submit-queue = <xx>; */
					/* complete-queue  = <25> */
					/* debug; */
					channel		= <9>;
					flow		= <9>;
				};
				udmarx10 {
					receive;
					label		= "udmarx10";
					pool		= "pool-udma";
					/* submit-queue = <xx>; */
					/* complete-queue  = <26> */
					/* debug; */
					channel		= <10>;
					flow		= <10>;
				};
				udmarx11 {
					receive;
					label		= "udmarx11";
					pool		= "pool-udma";
					/* submit-queue = <xx>; */
					/* complete-queue  = <27> */
					/* debug; */
					channel		= <11>;
					flow		= <11>;
				};
			};
		};

		udma0 {
			compatible = "ti,keystone-udma";
		};

		padma: pktdma@2004000 {
			compatible = "ti,keystone-pktdma";
			reg = <0x2004000 0x100		/* 0 - global  */
			       0x2004400 0x120		/* 1 - txchan  */
			       0x2004800 0x300		/* 2 - rxchan  */
			       0x2004c00 0x120		/* 3 - txsched */
			       0x2005000 0x400>;	/* 4 - rxflow  */
			/* loop-back;  */
			/* bigendian; */
			enable-all;
			debug;
			/* rx-priority = <0>; */
			/* tx-priority = <0>; */
			logical-queue-managers	= <4>;
			queues-per-queue-manager = <4096>;
			qm-base-address = <0x23a80000 0x23a90000
					   0x23aa0000 0x23ab0000>;

			channels {
				nettx0 {
					transmit;
					label		= "nettx0";
					pool		= "pool-net";
					submit-queue	= <648>;
					/* complete-queue = <xx>; */
					/* debug; */
					/* channel = <0>; */
					/* priority = <1>; */
				};
				nettx1 {
					transmit;
					label		= "nettx1";
					pool		= "pool-net";
					submit-queue	= <648>;
					/* complete-queue = <xx>; */
					/* debug; */
					/* channel = <0>; */
					/* priority = <1>; */
				};
				netrx0 {
					receive;
					label		= "netrx0";
					pool		= "pool-net";
					/* submit-queue   = <xx>; */
					complete-queue = <8704>;
					/* debug; */
					/* channel = <0>; */
					flow		= <22>;
				};
				netrx1 {
					receive;
					label		= "netrx1";
					pool		= "pool-net";
					/* submit-queue   = <xx>; */
					complete-queue = <8705>;
					/* debug; */
					/* channel = <0>; */
					flow		= <23>;
				};
				patx-pdsp0 {
					transmit;
					label		= "patx-pdsp0";
					pool		= "pool-net";
					submit-queue	= <640>;
					complete-queue = <8706>;
					/* debug; */
					/* channel = <xx>; */
					/* priority = <1>; */
				};
				patx-pdsp5-0 {
					transmit;
					label		= "patx-pdsp5-0";
					pool		= "pool-net";
					submit-queue	= <645>;
					complete-queue = <8707>;
					/* debug; */
					/* channel = <xx>; */
					/* priority = <1>; */
				};
				patx-pdsp5-1 {
					transmit;
					label		= "patx-pdsp5-1";
					pool		= "pool-net";
					submit-queue	= <645>;
					/* complete-queue = <xx>; */
					/* debug; */
					/* channel = <xx>; */
					/* priority = <1>; */
				};
				parx {
					receive;
					label		= "parx";
					pool		= "pool-net";
					/* submit-queue   = <xx>; */
					/* complete-queue = <xx>; */
					/* debug; */
					/* channel = <0>; */
					flow		= <31>;
				};
			};
		};

		mdio: mdio@2090300 {
			compatible	= "ti,davinci_mdio";
			#address-cells = <1>;
			#size-cells = <0>;
			reg		= <0x2090300 0x100>;
			bus_freq	= <500000>;
			clocks		= <&clkcpgmac>;
			clock-names	= "fck";

			phy0: phy@0 {
				compatible = "marvell,88e1111";
				reg = <0>;
			};
			phy1: phy@1 {
				compatible = "marvell,88e1111";
				reg = <1>;
			};
		};

		netcp: netcp@2090000 {
			reg = <0x2090000 0xf00
				0x2620110 0x8>;
			compatible = "ti,keystone-netcp";

			clocks = <&clkpa>, <&clkcpgmac>;
			clock-names = "clk_pa", "clk_cpgmac";

			interfaces {
				interface-0 {
					rx-channel = "netrx0";
					rx-queue-depth = <128 0 0 0>;
					rx-buffer-size = <1500 0 0 0>;
					efuse-mac = <1>;
					/*local-mac-address = [02 18 31 7e 3e 6e]; */
				};
				interface-1 {
					rx-channel = "netrx1";
					rx-queue-depth = <128 128 0 0>;
					rx-buffer-size = <1500 4096 0 0>;
					efuse-mac = <0>;
					local-mac-address = [02 18 31 7e 3e 6f];
				};
			};

			cpsw: cpsw@2090000 {
				label = "keystone-cpsw";
				serdes_at_probe = <1>;

				intf_tx_queues = <4>;

				sgmii_module_ofs  = <0x100>;
				switch_module_ofs = <0x800>;
				host_port_reg_ofs = <0x834>;
				slave_reg_ofs	  = <0x860>;
				sliver_reg_ofs	  = <0x900>;
				hw_stats_reg_ofs  = <0xb00>;
				ale_reg_ofs	  = <0xe00>;

				num_slaves  = <2>;
				ale_ageout  = <30>;
				ale_entries = <1024>;
				ale_ports   = <3>;

				multi-interface;
				num-interfaces = <2>;
				slaves-per-interface = <1>;

				interfaces {
					interface-0 {
						slave_port = <0>;
						tx-channel = "nettx0";
						tx_queue_depth = <32>;
						intf_tx_queues = <6>;
					};
					interface-1 {
						slave_port = <1>;
						tx-channel = "nettx1";
						tx_queue_depth = <32>;
						intf_tx_queues = <6>;
					};
				};

				slaves {
					slave0 {
						label		= "slave0";
						link-interface	= <1>;
						phy-handle	= <&phy0>;
					};
					slave1 {
						label		= "slave1";
						link-interface	= <1>;
						phy-handle	= <&phy1>;
					};

				};
			};
			pa: pa@2000000 {
				label = "keystone-pa";
				checksum-offload	= <2>;
				txhook-order		= <10>;
				txhook-softcsum		= <40>;
				rxhook-order		= <10>;

				tx_cmd_queue_depth	= <32>;
				tx_data_queue_depth	= <32>;
				rx_pool_depth		= <64>;
				rx_buffer_size		= <128>;
				lut-ranges		= < 0 47 60 63>;
			};
		};
	};
};
